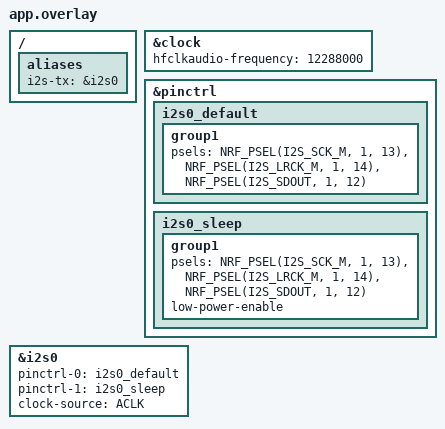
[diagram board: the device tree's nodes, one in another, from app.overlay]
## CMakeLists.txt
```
cmake_minimum_required(VERSION 3.20.0)
find_package(Zephyr REQUIRED HINTS $ENV{ZEPHYR_BASE})

project(ble_audio_receiver)

# Clean, scannable, properly indented compilation targets
target_sources(app PRIVATE
    src/main.c
    src/dsp/audio_dsp.c
    src/diag/audio_telemetry.c
    src/hw/board_buttons.c
    src/hw/board_leds.c
    src/dac/audio_i2s.c
    src/ble/ble_conn_control.c
    src/ble/ble_audio_stream.c
    src/ble/ble_bap_unicast_server.c
    src/ble/ble_bap_broadcast_sink.c
)

# Architectural Best Practice: Expose your source root globally.
# This lets your C files use `#include "ble_auracast.h"` directly 
# instead of relying on sloppy relative subfolder tracks.
zephyr_include_directories(src/ble)
```

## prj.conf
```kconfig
# --- Bluetooth General Settings ---
CONFIG_BT=y
CONFIG_BT_PERIPHERAL=y
CONFIG_BT_DEVICE_NAME="AuraLink"
CONFIG_BT_EXT_ADV=y
CONFIG_BT_MAX_CONN=1

# --- Security, Multi-Device Bonding & Persistence Across Reboots ---
CONFIG_BT_SMP=y
CONFIG_BT_SIGNING=y
CONFIG_BT_BONDABLE=y
CONFIG_BT_MAX_PAIRED=4
CONFIG_BT_KEYS_OVERWRITE_OLDEST=y
CONFIG_BT_SMP_ALLOW_UNAUTH_OVERWRITE=y

CONFIG_FLASH=y
CONFIG_FLASH_PAGE_LAYOUT=y
CONFIG_FLASH_MAP=y
CONFIG_NVS=y
CONFIG_SETTINGS=y
CONFIG_SETTINGS_NVS=y
CONFIG_BT_SETTINGS=y
CONFIG_BT_SETTINGS_CCC_STORE_ON_WRITE=y

# --- Logging Subsystem ---
CONFIG_LOG=y

# --- Core Audio & LC3 Codec Features ---
CONFIG_BT_AUDIO=y
CONFIG_BT_ISO_PERIPHERAL=y
CONFIG_FPU=y
CONFIG_LIBLC3=y

# --- BAP Unicast Server & Volume Control Renderer ---
CONFIG_BT_BAP_UNICAST_SERVER=y
CONFIG_BT_ASCS=y
CONFIG_BT_ASCS_MAX_ASE_SNK_COUNT=2
CONFIG_BT_VCP_VOL_REND=y

# --- Official Phone-Assisted Auracast Sink (BASS Scan Delegator + PAST + Sink) ---
CONFIG_BT_OBSERVER=y
CONFIG_BT_PER_ADV_SYNC=y
CONFIG_BT_PER_ADV_SYNC_TRANSFER_RECEIVER=y
CONFIG_BT_ISO_SYNC_RECEIVER=y
CONFIG_BT_BAP_SCAN_DELEGATOR=y
CONFIG_BT_BAP_SCAN_DELEGATOR_RECV_STATE_COUNT=2
CONFIG_BT_BAP_BASS_MAX_SUBGROUPS=2
CONFIG_BT_BAP_BROADCAST_SINK=y
CONFIG_BT_BAP_BROADCAST_SNK_SUBGROUP_COUNT=2
CONFIG_BT_BAP_BROADCAST_SNK_STREAM_COUNT=2

# --- Buffer Tuning for High-Throughput HCI Channels ---
CONFIG_BT_BUF_EVT_RX_SIZE=255
CONFIG_BT_BUF_ACL_RX_SIZE=255
CONFIG_BT_BUF_ACL_TX_SIZE=251
CONFIG_BT_BUF_CMD_TX_SIZE=255

# --- Compatibility Layer for Android / Samsung / Pixel Source Stacks ---
CONFIG_BT_CAP_ACCEPTOR=y
CONFIG_BT_ISO_RX_BUF_COUNT=16
CONFIG_BT_ISO_TX_BUF_COUNT=2
CONFIG_BT_ISO_RX_MTU=251
CONFIG_BT_ISO_MAX_CHAN=4
CONFIG_BT_AUDIO_CODEC_CFG_MAX_DATA_SIZE=32
CONFIG_BT_AUDIO_CODEC_CFG_MAX_METADATA_SIZE=255
CONFIG_BT_ATT_PREPARE_COUNT=32

CONFIG_BT_L2CAP_TX_MTU=247
CONFIG_BT_BUF_ACL_TX_COUNT=8

# --- Thread & Workqueue Stack Allocations (Prevents BASE / BASS Stack Overflow) ---
CONFIG_MAIN_STACK_SIZE=4096
CONFIG_SYSTEM_WORKQUEUE_STACK_SIZE=4096
CONFIG_BT_RX_STACK_SIZE=8192

# --- Timing Constraints Optimization ---
CONFIG_BT_PERIPHERAL_PREF_MIN_INT=50
CONFIG_BT_PERIPHERAL_PREF_MAX_INT=70
CONFIG_BT_PERIPHERAL_PREF_LATENCY=0
CONFIG_BT_PERIPHERAL_PREF_TIMEOUT=400

# Dynamic DB unlocks ASCS, VCS & BASS
CONFIG_BT_GATT_DYNAMIC_DB=y
CONFIG_BT_GATT_CACHING=y
CONFIG_BT_GATT_SERVICE_CHANGED=y

# --- I2S Driver Subsystem ---
CONFIG_I2S=y
CONFIG_I2S_NRFX=y
CONFIG_I2S_NRFX_TX_BLOCK_COUNT=24

CONFIG_CLOCK_CONTROL=y
CONFIG_CLOCK_CONTROL_NRF=y
```

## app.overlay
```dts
/ {
    aliases {
        i2s-tx = &i2s0;
    };
};

/* 1. Tune the nRF5340 Audio PLL to 12.288 MHz */
&clock {
    status = "okay";
    hfclkaudio-frequency = <12288000>;
};

&pinctrl {
    i2s0_default: i2s0_default {
        group1 {
            psels = <NRF_PSEL(I2S_SCK_M, 1, 13)>, /* BCLK  -> P1.13 */
                    <NRF_PSEL(I2S_LRCK_M, 1, 14)>, /* WSEL  -> P1.14 */
                    <NRF_PSEL(I2S_SDOUT, 1, 12)>;  /* DIN   -> P1.12 */
        };
    };

    i2s0_sleep: i2s0_sleep {
        group1 {
            psels = <NRF_PSEL(I2S_SCK_M, 1, 13)>,
                    <NRF_PSEL(I2S_LRCK_M, 1, 14)>,
                    <NRF_PSEL(I2S_SDOUT, 1, 12)>;
            low-power-enable;
        };
    };
};

&i2s0 {
    status = "okay";
    pinctrl-0 = <&i2s0_default>;
    pinctrl-1 = <&i2s0_sleep>;
    pinctrl-names = "default", "sleep";
    clock-source = "ACLK";
};
```

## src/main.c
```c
#include "dac/audio_i2s.h"
#include "hw/board_buttons.h"
#include "hw/board_leds.h"
#include "ble/ble_audio_stream.h"
#include "ble/ble_bap_unicast_server.h"
#include "ble/ble_bap_broadcast_sink.h"
#include "ble/ble_conn_control.h"

#include <zephyr/kernel.h>
#include <zephyr/bluetooth/bluetooth.h>
#include <zephyr/settings/settings.h>
#include <zephyr/logging/log.h>

LOG_MODULE_REGISTER(main, LOG_LEVEL_INF);

int
main(void)
{
    int err;

    LOG_INF("=== AuraLink LE Audio Receiver Starting ===");

    board_leds_init();

    err = audio_i2s_init();
    if (err != 0)
    {
        LOG_ERR("Audio I2S / DSP subsystem init failed (err %d)", err);
        board_leds_notify_event(LED_EVT_ERROR);
        return err;
    }

    board_buttons_init();

    err = bt_enable(NULL);
    if (err != 0)
    {
        LOG_ERR("Bluetooth stack init failed (err %d)", err);
        board_leds_notify_event(LED_EVT_ERROR);
        return err;
    }

    if (IS_ENABLED(CONFIG_SETTINGS))
    {
        settings_load();
    }

    ble_audio_stream_init();
    ble_bap_unicast_server_start();
    ble_bap_broadcast_sink_start();
    ble_conn_control_init();

    LOG_INF("=== AuraLink Ready (Unicast + Auracast Sink) ===");
    return 0;
}
```
